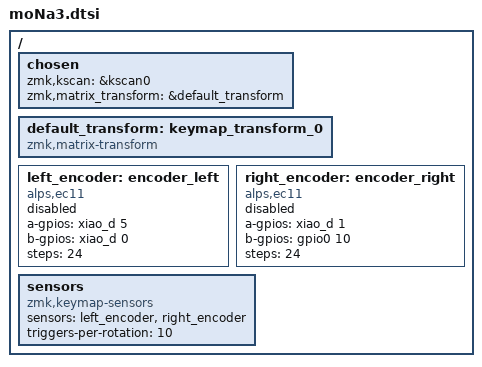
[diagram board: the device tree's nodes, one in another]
#include <dt-bindings/zmk/matrix_transform.h>

/ {
    chosen {
        zmk,kscan = &kscan0;
        zmk,matrix_transform = &default_transform;
    };

    default_transform: keymap_transform_0 {
        compatible = "zmk,matrix-transform";
    };
    

    left_encoder: encoder_left {
        compatible = "alps,ec11";
        a-gpios = <&xiao_d 5 (GPIO_ACTIVE_HIGH | GPIO_PULL_UP)>;
        b-gpios = <&xiao_d 0 (GPIO_ACTIVE_HIGH | GPIO_PULL_UP)>;
        steps = <24>;
        status = "disabled";
    };

    right_encoder: encoder_right {
        compatible = "alps,ec11";
        a-gpios = <&xiao_d 1 (GPIO_ACTIVE_HIGH | GPIO_PULL_UP)>;
        b-gpios = <&gpio0 10 (GPIO_ACTIVE_HIGH | GPIO_PULL_UP)>;
        steps = <24>;
        status = "disabled";
    };

    sensors: sensors {
        compatible = "zmk,keymap-sensors";
        sensors = <&left_encoder &right_encoder>;
        triggers-per-rotation = <10>;
    };
};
